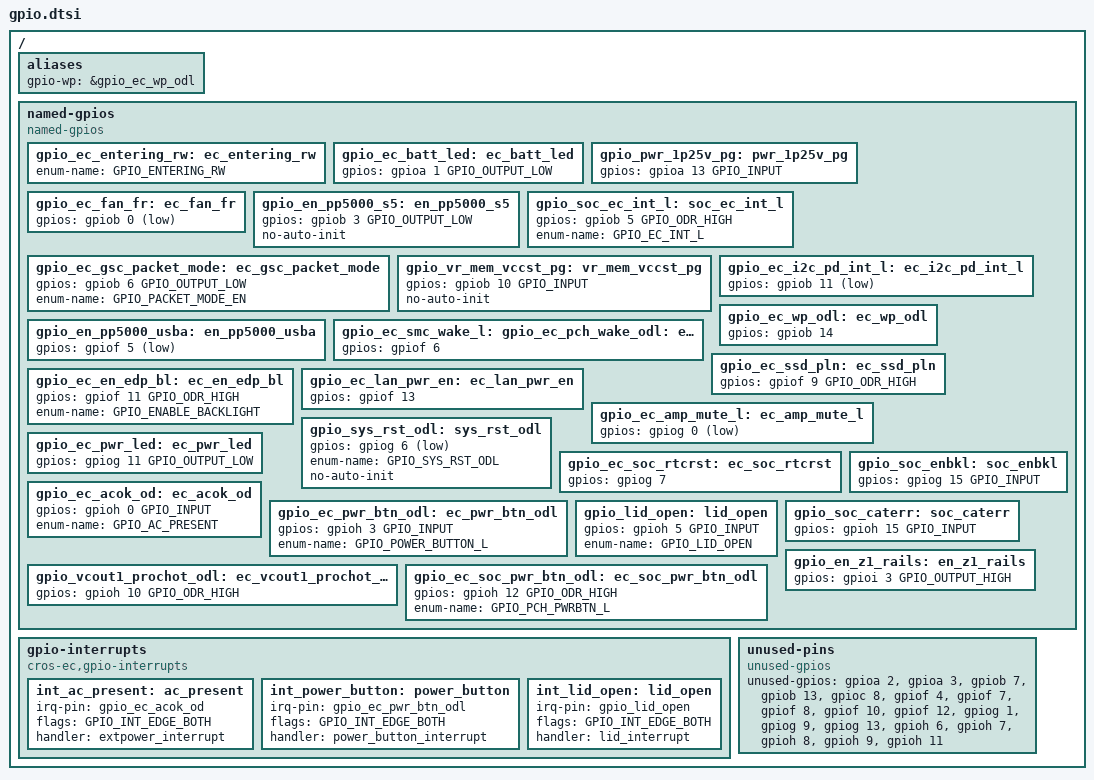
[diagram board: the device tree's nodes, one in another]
/* Copyright 2025 The ChromiumOS Authors
 * Use of this source code is governed by a BSD-style license that can be
 * found in the LICENSE file.
 */

 / {
	aliases {
		gpio-wp = &gpio_ec_wp_odl;
	};

	named-gpios {
		compatible = "named-gpios";

		/* The legacy system code requires GPIO_ENTERING_RW symbol */
		gpio_ec_entering_rw: ec_entering_rw {
			enum-name = "GPIO_ENTERING_RW";
		};

		gpio_ec_batt_led: ec_batt_led { /* PM_BAT_STATUS_LED1 */
			gpios = <&gpioa 1 GPIO_OUTPUT_LOW>;
		};
		gpio_pwr_1p25v_pg: pwr_1p25v_pg {
			gpios = <&gpioa 13 GPIO_INPUT>;
		};
		gpio_ec_fan_fr: ec_fan_fr {
			gpios = <&gpiob 0 (GPIO_OUTPUT | GPIO_OPEN_DRAIN | GPIO_ACTIVE_LOW | GPIO_OUTPUT_INIT_LOW)>;
		};
		gpio_en_pp5000_s5: en_pp5000_s5 { /* ec_5valw_en */
			gpios = <&gpiob 3 GPIO_OUTPUT_LOW>;
			no-auto-init;
		};
		gpio_soc_ec_int_l: soc_ec_int_l {
			gpios = <&gpiob 5 GPIO_ODR_HIGH>;
			enum-name = "GPIO_EC_INT_L";
		};
		gpio_ec_gsc_packet_mode: ec_gsc_packet_mode {
			gpios = <&gpiob 6 GPIO_OUTPUT_LOW>;
			enum-name = "GPIO_PACKET_MODE_EN";
		};
		gpio_vr_mem_vccst_pg: vr_mem_vccst_pg {
			gpios = <&gpiob 10 GPIO_INPUT>;
			no-auto-init;
		};
		gpio_ec_i2c_pd_int_l: ec_i2c_pd_int_l {
			gpios = <&gpiob 11 (GPIO_INPUT | GPIO_ACTIVE_LOW)>;
		};
		gpio_ec_wp_odl: ec_wp_odl { /* SPI_WP_H1 */
			gpios = <&gpiob 14 (GPIO_INPUT | GPIO_VOLTAGE_1P8)>;
		};
		gpio_en_pp5000_usba: en_pp5000_usba {
			gpios = <&gpiof 5 (GPIO_OUTPUT | GPIO_ACTIVE_LOW | GPIO_OUTPUT_INIT_HIGH)>;
		};
		gpio_ec_smc_wake_l: ec_smc_wake_l {
			gpios = <&gpiof 6 (GPIO_ODR_HIGH | GPIO_VOLTAGE_1P8)>;
		};
		gpio_ec_ssd_pln: ec_ssd_pln {
			gpios = <&gpiof 9 GPIO_ODR_HIGH>;
		};
		gpio_ec_en_edp_bl: ec_en_edp_bl { /* EC_BKOFF# */
			gpios = <&gpiof 11 GPIO_ODR_HIGH>;
			enum-name = "GPIO_ENABLE_BACKLIGHT";
		};
		gpio_ec_lan_pwr_en: ec_lan_pwr_en {
			gpios = <&gpiof 13 (GPIO_OUTPUT | GPIO_ACTIVE_HIGH | GPIO_OUTPUT_INIT_LOW)>;
		};
		gpio_ec_amp_mute_l: ec_amp_mute_l {
			gpios = <&gpiog 0 (GPIO_ODR_LOW | GPIO_ACTIVE_LOW)>;
		};
		gpio_sys_rst_odl: sys_rst_odl {
			gpios = <&gpiog 6 (GPIO_ACTIVE_LOW | GPIO_OPEN_DRAIN | GPIO_VOLTAGE_1P8)>;
			enum-name = "GPIO_SYS_RST_ODL";
			no-auto-init;
		};
		gpio_ec_soc_rtcrst: ec_soc_rtcrst {
			gpios = <&gpiog 7 (GPIO_OUTPUT | GPIO_ACTIVE_HIGH | GPIO_OUTPUT_INIT_LOW)>;
		};
		gpio_ec_pwr_led: ec_pwr_led { /* PM_BAT_STATUS_LED2 */
			gpios = <&gpiog 11 GPIO_OUTPUT_LOW>;
		};
		gpio_soc_enbkl: soc_enbkl {
			gpios = <&gpiog 15 GPIO_INPUT>;
		};
		gpio_ec_acok_od: ec_acok_od {
			gpios = <&gpioh 0 GPIO_INPUT>;
			enum-name = "GPIO_AC_PRESENT";
		};
		gpio_ec_pwr_btn_odl: ec_pwr_btn_odl {
			gpios = <&gpioh 3 GPIO_INPUT>;
			enum-name = "GPIO_POWER_BUTTON_L";
		};
		gpio_lid_open: lid_open {
			gpios = <&gpioh 5 GPIO_INPUT>;
			enum-name = "GPIO_LID_OPEN";
		};
		gpio_vcout1_prochot_odl: ec_vcout1_prochot_odl {
			gpios = <&gpioh 10 GPIO_ODR_HIGH>;
		};
		gpio_ec_soc_pwr_btn_odl: ec_soc_pwr_btn_odl {
			gpios = <&gpioh 12 GPIO_ODR_HIGH>;
			enum-name = "GPIO_PCH_PWRBTN_L";
		};
		gpio_soc_caterr: soc_caterr {
			gpios = <&gpioh 15 GPIO_INPUT>;
		};
		gpio_en_z1_rails: en_z1_rails {	/* PRIM_VR_EN, EN_PP3300_Z1 */
			gpios = <&gpioi 3 GPIO_OUTPUT_HIGH>;
		};
	};

	gpio-interrupts {
		compatible = "cros-ec,gpio-interrupts";
		int_ac_present: ac_present {
			irq-pin = <&gpio_ec_acok_od>;
			flags = <GPIO_INT_EDGE_BOTH>;
			handler = "extpower_interrupt";
		};
		int_power_button: power_button {
			irq-pin = <&gpio_ec_pwr_btn_odl>;
			flags = <GPIO_INT_EDGE_BOTH>;
			handler = "power_button_interrupt";
		};
		int_lid_open: lid_open {
			irq-pin = <&gpio_lid_open>;
			flags = <GPIO_INT_EDGE_BOTH>;
			handler = "lid_interrupt";
		};
	};

	unused-pins {
		compatible = "unused-gpios";
		unused-gpios =
			<&gpioa 2 0>,
			<&gpioa 3 0>,
			<&gpiob 7 0>,
			<&gpiob 13 0>,
			<&gpioc 8 0>,
			<&gpiof 4 0>,
			<&gpiof 7 0>,
			<&gpiof 8 0>,
			<&gpiof 10 0>,
			<&gpiof 12 0>,
			<&gpiog 1 0>,
			<&gpiog 9 0>,
			<&gpiog 13 0>,
			<&gpioh 6 0>,
			<&gpioh 7 0>,
			<&gpioh 8 0>,
			<&gpioh 9 0>,
			<&gpioh 11 0>;
	};
};

/*
 * Aliases to common names
 */
gpio_ec_pch_wake_odl: &gpio_ec_smc_wake_l {};
